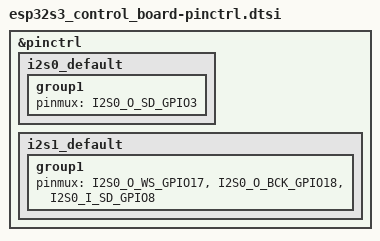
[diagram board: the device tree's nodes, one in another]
/*
 * Copyright (c) 2024 Espressif Systems (Shanghai) Co., Ltd.
 *
 * SPDX-License-Identifier: Apache-2.0
 */

#include <zephyr/dt-bindings/pinctrl/esp-pinctrl-common.h>
#include <dt-bindings/pinctrl/esp32s3-pinctrl.h>
#include <zephyr/dt-bindings/pinctrl/esp32s3-gpio-sigmap.h>

&pinctrl {
	i2s0_default: i2s0_default {
		group1 {
			pinmux = <I2S0_O_SD_GPIO3>;
		};
	};
	i2s1_default: i2s1_default {
		group1 {
			pinmux = <I2S0_O_WS_GPIO17>,
					 <I2S0_O_BCK_GPIO18>,
					 <I2S0_I_SD_GPIO8>;
		};
	};
};
